# STM32H7B3x register map
File version: 2.2
CPU: CM7 r0p1, little endian, MPU, FPU, 4 interrupt priority bits
Registers are 32-bit, read-write, reset 0x0 unless marked. A register's access mark holds for its fields unless they carry their own. Offsets are from the block's base; [hi:lo] are bit positions; lines under a group give offsets from that group; {n}, {i} and the like mark numbered series; 'fields as' and 'values as' point back to an identical list.

## BDMA1 — BDMA
Base 0x48022C00
Same registers: BDMA2 0x58025400
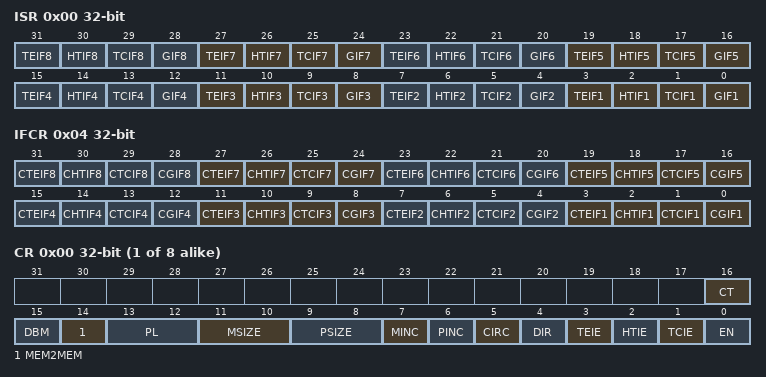
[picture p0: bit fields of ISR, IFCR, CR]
0x00 ISR ro — DMA interrupt status register
  [4n-1] TEIF{n} (n=1..8) — Channel x transfer error flag (x = 1..8) This bit is set by hardware. It is cleared by software writing 1 to the corresponding bit in the DMA_IFCR register.
    on read: 0=NoError (No transfer error on channel x); 1=Error (A transfer error occurred on channel x)
  [4n-2] HTIF{n} (n=1..8) — Channel x half transfer flag (x = 1..8) This bit is set by hardware. It is cleared by software writing 1 to the corresponding bit in the DMA_IFCR register.
    on read: 0=NotHalf (No half transfer event on channel x); 1=Half (A half transfer event occurred on channel x)
  [4n-3] TCIF{n} (n=1..8) — Channel x transfer complete flag (x = 1..8) This bit is set by hardware. It is cleared by software writing 1 to the corresponding bit in the DMA_IFCR register.
    on read: 0=NotComplete (No transfer complete event on channel x); 1=Complete (A transfer complete event occurred on channel x)
  [4n-4] GIF{n} (n=1..8) — Channel x global interrupt flag (x = 1..8) This bit is set by hardware. It is cleared by software writing 1 to the corresponding bit in the DMA_IFCR register.
    on read: 0=NoEvent (No TE, HT or TC event on channel x); 1=Event (A TE, HT or TC event occurred on channel x)
0x04 IFCR wo — DMA interrupt flag clear register
  [4n-1] CTEIF{n} (n=1..8) — Channel x transfer error clear This bit is set and cleared by software.
    on write: 1=Clear the corresponding TEIFx flag
  [4n-2] CHTIF{n} (n=1..8) — Channel x half transfer clear This bit is set and cleared by software.
    on write: 1=Clear the corresponding HTIFx flag
  [4n-3] CTCIF{n} (n=1..8) — Channel x transfer complete clear This bit is set and cleared by software.
    on write: 1=Clear the corresponding TCIFx flag
  [4n-4] CGIF{n} (n=1..8) — Channel x global interrupt clear This bit is set and cleared by software.
    on write: 1=Clear the corresponding CGIFx flag
{0x8+0x14*i} CH{i} (i=0..7) group — Channel cluster: CCR?, CNDTR?, CPAR?, CM0AR? and CM1AR registers?
  0x00 CR — DMA channel x configuration register
    [16] CT — Current target memory in double-buffer mode
      0=Memory0 (The current target memory is Memory 0); 1=Memory1 (The current target memory is Memory 1)
    [15] DBM — Double-buffer mode
      0=Disabled (No buffer switching at the end of transfer); 1=Enabled (Memory target switched at the end of the DMA transfer)
    [14] MEM2MEM — Memory to memory mode This bit is set and cleared by software.
      0=Disabled (Memory-to-memory mode disabled); 1=Enabled (Memory-to-memory mode enabled)
    [13:12] PL — Channel priority level These bits are set and cleared by software.
      0=Low; 1=Medium; 2=High; 3=VeryHigh
    [11:10] MSIZE — Memory size These bits are set and cleared by software.
      0=Bits8 (Byte (8-bit)); 1=Bits16 (Half-word (16-bit)); 2=Bits32 (Word (32-bit))
    [9:8] PSIZE — Peripheral size These bits are set and cleared by software.
      values as MSIZE
    [7] MINC — Memory increment mode This bit is set and cleared by software.
      0=Fixed (Address pointer is fixed); 1=Incremented (Address pointer is incremented after each data transfer)
    [6] PINC — Peripheral increment mode This bit is set and cleared by software.
      values as MINC
    [5] CIRC — Circular mode This bit is set and cleared by software.
      0=Disabled (Circular mode disabled); 1=Enabled (Circular mode enabled)
    [4] DIR — Data transfer direction This bit is set and cleared by software.
      0=PeripheralToMemory; 1=MemoryToPeripheral
    [3] TEIE — Transfer error interrupt enable This bit is set and cleared by software.
      0=Disabled (TE interrupt disabled); 1=Enabled (TE interrupt enabled)
    [2] HTIE — Half transfer interrupt enable This bit is set and cleared by software.
      0=Disabled (HT interrupt disabled); 1=Enabled (HT interrupt enabled)
    [1] TCIE — Transfer complete interrupt enable This bit is set and cleared by software.
      0=Disabled (TC interrupt disabled); 1=Enabled (TC interrupt enabled)
    [0] EN — Channel enable This bit is set and cleared by software.
      0=Disabled (Channel disabled); 1=Enabled (Channel enabled)
  0x04 NDTR — DMA channel x number of data register
    [15:0] NDT — Number of data to transfer Number of data to be transferred (0 up to 65535). This register can only be written when the channel is disabled. Once the channel is enabled, this register is read-only, indicating the remaining bytes to be transmitted. This register decrements after each DMA transfer. Once the transfer is completed, this register can either stay at zero or be reloaded automatically by the value previously programmed if the channel is configured in auto-reload mode. If this register is zero, no transaction can be served whether the channel is enabled or not.
  0x08 PAR — This register must not be written when the channel is enabled.
    [31:0] PA — Peripheral address Base address of the peripheral data register from/to which the data will be read/written. When PSIZE is 01 (16-bit), the PA[0] bit is ignored. Access is automatically aligned to a half-word address. When PSIZE is 10 (32-bit), PA[1:0] are ignored. Access is automatically aligned to a word address.
  0x0C M0AR — This register must not be written when the channel is enabled.
    [31:0] MA — Memory address Base address of the memory area from/to which the data will be read/written. When MSIZE is 01 (16-bit), the MA[0] bit is ignored. Access is automatically aligned to a half-word address. When MSIZE is 10 (32-bit), MA[1:0] are ignored. Access is automatically aligned to a word address.
  0x10 M1AR — This register must not be written when the channel is enabled
    [31:0] MA — Memory address
